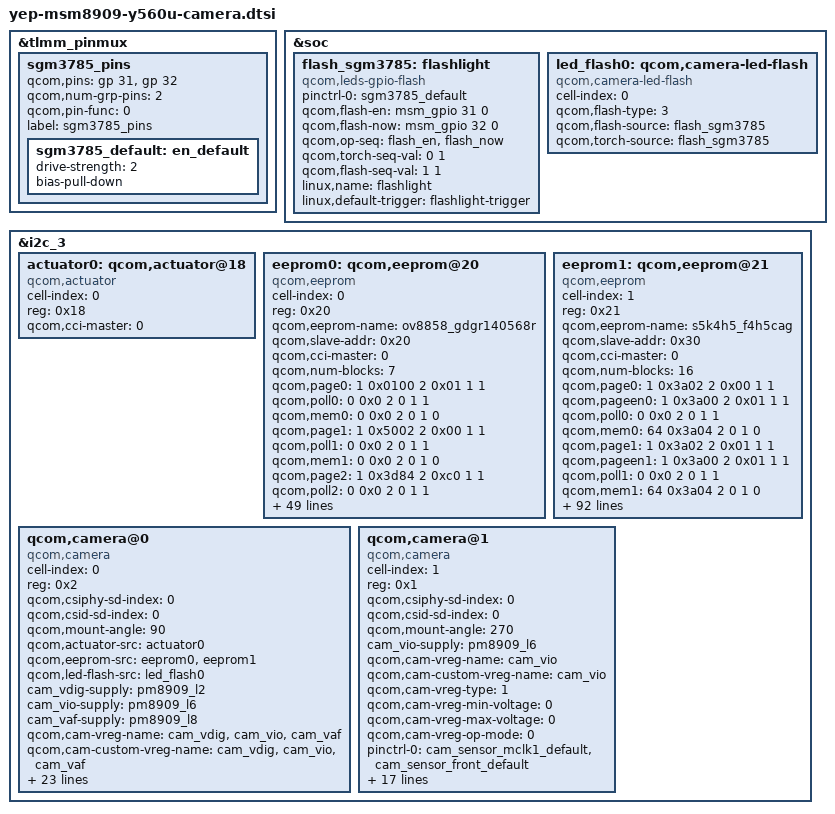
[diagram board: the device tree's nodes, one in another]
/*
 * Copyright (c) 2014, The Linux Foundation. All rights reserved.
 *
 * This program is free software; you can redistribute it and/or modify
 * it under the terms of the GNU General Public License version 2 and
 * only version 2 as published by the Free Software Foundation.
 *
 * This program is distributed in the hope that it will be useful,
 * but WITHOUT ANY WARRANTY; without even the implied warranty of
 * MERCHANTABILITY or FITNESS FOR A PARTICULAR PURPOSE.  See the
 * GNU General Public License for more details.
 */
 
/*  Date            Author          Why
    2014-01-12      litao2          creat
*/ 
 
&tlmm_pinmux {
	sgm3785_pins {
		qcom,pins = <&gp 31>, <&gp 32>;
		qcom,num-grp-pins = <2>;
		qcom,pin-func = <0>;
		label = "sgm3785_pins";
		sgm3785_default: en_default {
		drive-strength = <2>;
		bias-pull-down;
		};
	};
};

&soc {
	flash_sgm3785:flashlight {
		compatible = "qcom,leds-gpio-flash";
		status = "okay";
		pinctrl-names = "flash_default";
		pinctrl-0 = <&sgm3785_default>;
		qcom,flash-en = <&msm_gpio 31 0>;
		qcom,flash-now = <&msm_gpio 32 0>;
		qcom,op-seq = "flash_en", "flash_now";
		qcom,torch-seq-val = <0 1>;
		qcom,flash-seq-val = <1 1>;
		linux,name = "flashlight";
		linux,default-trigger = "flashlight-trigger";
	};
	led_flash0: qcom,camera-led-flash {
		cell-index = <0>;
		compatible = "qcom,camera-led-flash";
		qcom,flash-type = <3>;
		qcom,flash-source = <&flash_sgm3785>;
		qcom,torch-source = <&flash_sgm3785>;
	};
};

&i2c_3 {

	actuator0: qcom,actuator@18 {
		cell-index = <0>;
		reg = <0x18>;
		compatible = "qcom,actuator";
		qcom,cci-master = <0>;
	};
	
	eeprom0: qcom,eeprom@20 {
		cell-index = <0>;
		reg = <0x20>;
		qcom,eeprom-name = "ov8858_gdgr140568r";
		compatible = "qcom,eeprom";
		qcom,slave-addr = <0x20>;
		qcom,cci-master = <0>;
		qcom,num-blocks = <7>;
		qcom,page0 = <1 0x0100 2 0x01 1 1>;
		qcom,poll0 = <0 0x0 2 0 1 1>;
		qcom,mem0 = <0 0x0 2 0 1 0>;
		
		qcom,page1 = <1 0x5002 2 0x00 1 1>;
		qcom,poll1 = <0 0x0 2 0 1 1>;
		qcom,mem1 = <0 0x0 2 0 1 0>;
		
		qcom,page2 = <1 0x3d84 2 0xc0 1 1>;
		qcom,poll2 = <0 0x0 2 0 1 1>;
		qcom,mem2 = <0 0x3d00 2 0 1 0>;
		
		qcom,page3 = <1 0x3d88 2 0x7010 2 1>;
		qcom,poll3 = <0 0x0 2 0 1 1>;
		qcom,mem3 = <0 0x3d00 2 0 1 0>;
		
		qcom,page4 = <1 0x3d8A 2 0x720a 2 1>;
		qcom,poll4 = <0 0x0 2 0 1 1>;
		qcom,mem4 = <0 0x0 2 0 1 1>;
		
		qcom,page5 = <1 0x3d81 2 0x01 1 10>;
		qcom,poll5 = <0 0x0 2 0 1 1>;
		qcom,mem5 = <507 0x7010 2 0 1 0>;
		
		qcom,page6 = <1 0x5002 2 0x08 1 1>;
		qcom,poll6 = <0 0x0 2 0 1 1>;
		qcom,mem6 = <0 0x0 2 0 1 0>;
		
		cam_vdig-supply = <&pm8909_l2>;
		cam_vio-supply = <&pm8909_l6>;
		qcom,cam-vreg-name = "cam_vdig","cam_vio";
		qcom,cam-custom-vreg-name = "cam_vdig","cam_vio";
		qcom,cam-vreg-type = <0 1>;
		qcom,cam-vreg-min-voltage = <1200000 0>;
		qcom,cam-vreg-max-voltage = <1200000 0>;
		qcom,cam-vreg-op-mode = <200000 0>;
		pinctrl-names = "cam_default", "cam_suspend";
		pinctrl-0 = <&cam_sensor_mclk0_default
				&cam_sensor_rear_default>;
		pinctrl-1 = <&cam_sensor_mclk0_sleep &cam_sensor_rear_sleep>;
		gpios = <&msm_gpio 26 0>,
			<&msm_gpio 35 0>,
			<&msm_gpio 34 0>,
			<&msm_gpio 3 0>,
			<&msm_gpio 93 0>;
		qcom,gpio-reset = <1>;
		qcom,gpio-standby = <2>;
		qcom,gpio-cameraid = <3>;
		qcom,gpio-vana = <4>;
		qcom,gpio-req-tbl-num = <0 1 2 3 4>;
		qcom,gpio-req-tbl-flags = <1 0 0 1 0>;
		qcom,gpio-req-tbl-label = "CAMIF_MCLK",
			"CAM_RESET",
			"CAM_STANDBY",
			"CAM_ID",
			"CAM_VANA";
		qcom,cam-power-seq-type = "sensor_vreg",
								  "sensor_gpio",
								  "sensor_vreg",
								  "sensor_gpio",
								  "sensor_gpio",
								  "sensor_gpio",
								  "sensor_gpio",								  
								  "sensor_clk",		
								  "sensor_i2c_mux";
		qcom,cam-power-seq-val = "cam_vio",
								 "sensor_gpio_vana",
								 "cam_vdig",								 								 
								 "sensor_gpio_standby",
								 "sensor_gpio_reset",
								 "sensor_gpio_standby",
								 "sensor_gpio_reset",
								 "sensor_cam_mclk",
								 "none";
		qcom,cam-power-seq-cfg-val = <0 1 0  0 0 1 1 24000000 0>;
		qcom,cam-power-seq-delay = <1 1 1 1 5 5 5 10 0>;
		clocks = <&clock_gcc clk_mclk0_clk_src>,
				<&clock_gcc clk_gcc_camss_mclk0_clk>;
		clock-names = "cam_src_clk", "cam_clk";
	};
	
	eeprom1: qcom,eeprom@21 {
		cell-index = <1>;
		reg = <0x21>;
		qcom,eeprom-name = "s5k4h5_f4h5cag";
		compatible = "qcom,eeprom";
		qcom,slave-addr = <0x30>;
		qcom,cci-master = <0>;
		qcom,num-blocks = <16>;
		
		qcom,page0 = <1 0x3a02 2 0x00 1 1>;
		qcom,pageen0 = <1 0x3a00 2 0x01 1 1>;
		qcom,poll0 = <0 0x0 2 0 1 1>;
		qcom,mem0 = <64 0x3a04 2 0 1 0>;

		qcom,page1 = <1 0x3a02 2 0x01 1 1>;
		qcom,pageen1 = <1 0x3a00 2 0x01 1 1>;
		qcom,poll1 = <0 0x0 2 0 1 1>;
		qcom,mem1 = <64 0x3a04 2 0 1 0>;

		qcom,page2 = <1 0x3a02 2 0x02 1 1>;
		qcom,pageen2 = <1 0x3a00 2 0x01 1 1>;
		qcom,poll2 = <0 0x0 2 0 1 1>;
		qcom,mem2 = <64 0x3a04 2 0 1 0>;

		qcom,page3 = <1 0x3a02 2 0x03 1 1>;
		qcom,pageen3 = <1 0x3a00 2 0x01 1 1>;
		qcom,poll3 = <0 0x0 2 0 1 1>;
		qcom,mem3 = <64 0x3a04 2 0 1 0>;

		qcom,page4 = <1 0x3a02 2 0x04 1 1>;
		qcom,pageen4 = <1 0x3a00 2 0x01 1 1>;
		qcom,poll4 = <0 0x0 2 0 1 1>;
		qcom,mem4 = <64 0x3a04 2 0 1 0>;

		qcom,page5 = <1 0x3a02 2 0x05 1 1>;
		qcom,pageen5 = <1 0x3a00 2 0x01 1 1>;
		qcom,poll5 = <0 0x0 2 0 1 1>;
		qcom,mem5 = <64 0x3a04 2 0 1 0>;

		qcom,page6 = <1 0x3a02 2 0x06 1 1>;
		qcom,pageen6 = <1 0x3a00 2 0x01 1 1>;
		qcom,poll6 = <0 0x0 2 0 1 1>;
		qcom,mem6 = <64 0x3a04 2 0 1 0>;

		qcom,page7 = <1 0x3a02 2 0x07 1 1>;
		qcom,pageen7 = <1 0x3a00 2 0x01 1 1>;
		qcom,poll7 = <0 0x0 2 0 1 1>;
		qcom,mem7 = <64 0x3a04 2 0 1 0>;

		qcom,page8 = <1 0x3a02 2 0x08 1 1>;
		qcom,pageen8 = <1 0x3a00 2 0x01 1 1>;
		qcom,poll8 = <0 0x0 2 0 1 1>;
		qcom,mem8 = <64 0x3a04 2 0 1 0>;

		qcom,page9 = <1 0x3a02 2 0x09 1 1>;
		qcom,pageen9 = <1 0x3a00 2 0x01 1 1>;
		qcom,poll9 = <0 0x0 2 0 1 1>;
		qcom,mem9 = <64 0x3a04 2 0 1 0>;

		qcom,page10 = <1 0x3a02 2 0x0a 1 1>;
		qcom,pageen10 = <1 0x3a00 2 0x01 1 1>;
		qcom,poll10 = <0 0x0 2 0 1 1>;
		qcom,mem10 = <64 0x3a04 2 0 1 0>;

		qcom,page11 = <1 0x3a02 2 0x0b 1 1>;
		qcom,pageen11 = <1 0x3a00 2 0x01 1 1>;
		qcom,poll11 = <0 0x0 2 0 1 1>;
		qcom,mem11 = <64 0x3a04 2 0 1 0>;

		qcom,page12 = <1 0x3a02 2 0x0c 1 1>;
		qcom,pageen12 = <1 0x3a00 2 0x01 1 1>;
		qcom,poll12 = <0 0x0 2 0 1 1>;
		qcom,mem12 = <64 0x3a04 2 0 1 0>;

		qcom,page13 = <1 0x3a02 2 0x0d 1 1>;
		qcom,pageen13 = <1 0x3a00 2 0x01 1 1>;
		qcom,poll13 = <0 0x0 2 0 1 1>;
		qcom,mem13 = <64 0x3a04 2 0 1 0>;

		qcom,page14 = <1 0x3a02 2 0x0e 1 1>;
		qcom,pageen14 = <1 0x3a00 2 0x01 1 1>;
		qcom,poll14 = <0 0x0 2 0 1 1>;
		qcom,mem14 = <64 0x3a04 2 0 1 0>;

		qcom,page15 = <1 0x3a02 2 0x0f 1 1>;
		qcom,pageen15 = <1 0x3a00 2 0x01 1 1>;
		qcom,poll15 = <0 0x0 2 0 1 1>;
		qcom,mem15 = <64 0x3a04 2 0 1 0>;
		
		cam_vdig-supply = <&pm8909_l2>;
		cam_vio-supply = <&pm8909_l6>;
		qcom,cam-vreg-name = "cam_vdig","cam_vio";
		qcom,cam-custom-vreg-name = "cam_vdig","cam_vio";
		qcom,cam-vreg-type = <0 1>;
		qcom,cam-vreg-min-voltage = <1200000 0>;
		qcom,cam-vreg-max-voltage = <1200000 0>;
		qcom,cam-vreg-op-mode = <200000 0>;
		pinctrl-names = "cam_default", "cam_suspend";
		pinctrl-0 = <&cam_sensor_mclk0_default
				&cam_sensor_rear_default>;
		pinctrl-1 = <&cam_sensor_mclk0_sleep &cam_sensor_rear_sleep>;
		gpios = <&msm_gpio 26 0>,
			<&msm_gpio 35 0>,
			<&msm_gpio 34 0>,
			<&msm_gpio 3 0>,
			<&msm_gpio 93 0>;
		qcom,gpio-reset = <1>;
		qcom,gpio-standby = <2>;
		qcom,gpio-cameraid = <3>;
		qcom,gpio-vana = <4>;
		qcom,gpio-req-tbl-num = <0 1 2 3 4>;
		qcom,gpio-req-tbl-flags = <1 0 0 1 0>;
		qcom,gpio-req-tbl-label = "CAMIF_MCLK",
			"CAM_RESET",
			"CAM_STANDBY",
			"CAM_ID",
			"CAM_VANA";
		qcom,cam-power-seq-type = "sensor_vreg",
								  "sensor_gpio",
								  "sensor_vreg",
								  "sensor_gpio",
								  "sensor_gpio",
								  "sensor_gpio",
								  "sensor_gpio",								  
								  "sensor_clk",		
								  "sensor_i2c_mux";
		qcom,cam-power-seq-val = "cam_vio",
								 "sensor_gpio_vana",
								 "cam_vdig",								 								 
								 "sensor_gpio_standby",
								 "sensor_gpio_reset",
								 "sensor_gpio_standby",
								 "sensor_gpio_reset",
								 "sensor_cam_mclk",
								 "none";
		qcom,cam-power-seq-cfg-val = <0 1 0  0 0 1 1 24000000 0>;
		qcom,cam-power-seq-delay = <1 1 1 1 5 5 5 10 0>;
		clocks = <&clock_gcc clk_mclk0_clk_src>,
				<&clock_gcc clk_gcc_camss_mclk0_clk>;
		clock-names = "cam_src_clk", "cam_clk";
	};
	qcom,camera@0 {
		cell-index = <0>;
		compatible = "qcom,camera";
		reg = <0x2>;
		qcom,csiphy-sd-index = <0>;
		qcom,csid-sd-index = <0>;
		qcom,mount-angle = <90>;
		qcom,actuator-src = <&actuator0>;
		qcom,eeprom-src = <&eeprom0 &eeprom1>;
		qcom,led-flash-src = <&led_flash0>;
		cam_vdig-supply = <&pm8909_l2>;
		cam_vio-supply = <&pm8909_l6>;
		cam_vaf-supply = <&pm8909_l8>;
		qcom,cam-vreg-name = "cam_vdig","cam_vio","cam_vaf";
		qcom,cam-custom-vreg-name = "cam_vdig","cam_vio","cam_vaf";
		qcom,cam-vreg-type = <0 1 0>;
		qcom,cam-vreg-min-voltage = <1200000 0 2850000>;
		qcom,cam-vreg-max-voltage = <1200000 0 2900000>;
		qcom,cam-vreg-op-mode = <200000 0 100000>;
		pinctrl-names = "cam_default", "cam_suspend";
		pinctrl-0 = <&cam_sensor_mclk0_default
				&cam_sensor_rear_default>;
		pinctrl-1 = <&cam_sensor_mclk0_sleep &cam_sensor_rear_sleep>;
		gpios = <&msm_gpio 26 0>,
			<&msm_gpio 35 0>,
			<&msm_gpio 34 0>,
			<&msm_gpio 3 0>,
			<&msm_gpio 93 0>;
		qcom,gpio-reset = <1>;
		qcom,gpio-standby = <2>;
		qcom,gpio-cameraid = <3>;
		qcom,gpio-vana = <4>;
		qcom,gpio-req-tbl-num = <0 1 2 3 4>;
		qcom,gpio-req-tbl-flags = <1 0 0 1 0>;
		qcom,gpio-req-tbl-label = "CAMIF_MCLK",
			"CAM_RESET",
			"CAM_STANDBY",
			"CAM_ID",
			"CAM_VANA";
		qcom,sensor-position = <0>;
		qcom,sensor-mode = <0>;
		qcom,cci-master = <0>;
		status = "ok";
		clocks = <&clock_gcc clk_mclk0_clk_src>,
				<&clock_gcc clk_gcc_camss_mclk0_clk>;
		clock-names = "cam_src_clk", "cam_clk";
	};

	qcom,camera@1 {
		cell-index = <1>;
		compatible = "qcom,camera";
		reg = <0x1>;
		qcom,csiphy-sd-index = <0>;
		qcom,csid-sd-index = <0>;
		qcom,mount-angle = <270>;
		cam_vio-supply = <&pm8909_l6>;
		qcom,cam-vreg-name = "cam_vio";
		qcom,cam-custom-vreg-name = "cam_vio";
		qcom,cam-vreg-type = <1>;
		qcom,cam-vreg-min-voltage = <0>;
		qcom,cam-vreg-max-voltage = <0>;
		qcom,cam-vreg-op-mode = <0>;
		pinctrl-names = "cam_default", "cam_suspend";
		pinctrl-0 = <&cam_sensor_mclk1_default &cam_sensor_front_default>;
		pinctrl-1 = <&cam_sensor_mclk1_sleep &cam_sensor_front_sleep>;
		gpios = <&msm_gpio 27 0>,
			<&msm_gpio 28 0>,
			<&msm_gpio 33 0>,
			<&msm_gpio 2 0>,
			<&msm_gpio 93 0>;
		qcom,gpio-reset = <1>;
		qcom,gpio-standby = <2>;
		qcom,gpio-cameraid = <3>;
		qcom,gpio-vana = <4>;
		qcom,gpio-req-tbl-num = <0 1 2 3 4>;
		qcom,gpio-req-tbl-flags = <1 0 0 1 0>;
		qcom,gpio-req-tbl-label = "CAMIF_MCLK",
			"CAM_RESET",
			"CAM_STANDBY",
			"CAM_ID",
			"CAM_VANA";
		qcom,sensor-position = <1>;
		qcom,sensor-mode = <0>;
		qcom,cci-master = <0>;
		status = "ok";
		clocks = <&clock_gcc clk_mclk1_clk_src>,
				<&clock_gcc clk_gcc_camss_mclk1_clk>;
		clock-names = "cam_src_clk", "cam_clk";
	};
	
};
